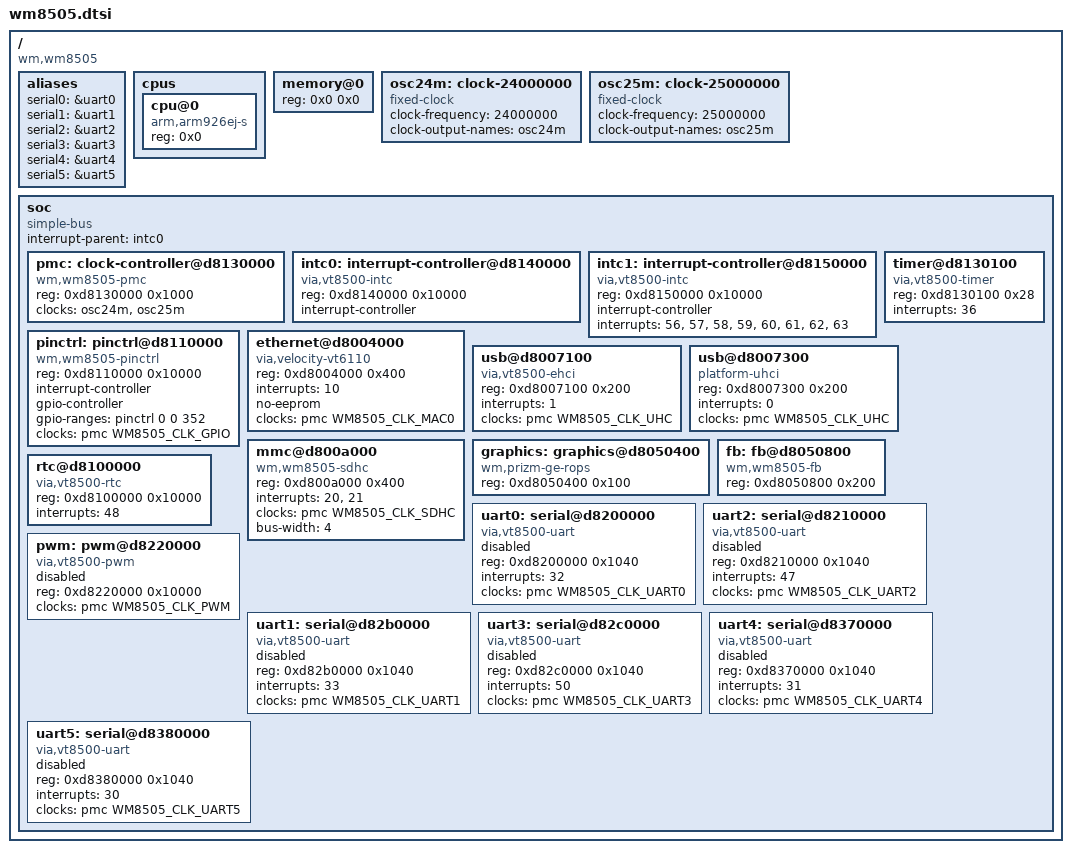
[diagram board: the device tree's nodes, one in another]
// SPDX-License-Identifier: GPL-2.0-or-later
/*
 * wm8505.dtsi - Device tree file for WonderMedia WM8505 SoC
 *
 * Copyright (C) 2012 Tony Prisk <linux@prisktech.co.nz>
 * Copyright (C) 2026 Logan Russell <me@lrussell.net>
 */

#include <dt-bindings/gpio/gpio.h>
#include <dt-bindings/interrupt-controller/irq.h>
#include <dt-bindings/clock/wm8505-clock.h>

/ {
	compatible = "wm,wm8505";
	#address-cells = <1>;
	#size-cells = <1>;

	aliases {
		serial0 = &uart0;
		serial1 = &uart1;
		serial2 = &uart2;
		serial3 = &uart3;
		serial4 = &uart4;
		serial5 = &uart5;
	};

	cpus {
		#address-cells = <1>;
		#size-cells = <0>;

		cpu@0 {
			compatible = "arm,arm926ej-s";
			device_type = "cpu";
			reg = <0x0>;
		};
	};

	memory@0 {
		device_type = "memory";
		reg = <0x0 0x0>;
	};

	osc24m: clock-24000000 {
		compatible = "fixed-clock";
		#clock-cells = <0>;
		clock-frequency = <24000000>;
		clock-output-names = "osc24m";
	};

	osc25m: clock-25000000 {
		compatible = "fixed-clock";
		#clock-cells = <0>;
		clock-frequency = <25000000>;
		clock-output-names = "osc25m";
	};

	soc {
		compatible = "simple-bus";
		#address-cells = <1>;
		#size-cells = <1>;
		ranges;
		interrupt-parent = <&intc0>;

		pmc: clock-controller@d8130000 {
			compatible = "wm,wm8505-pmc";
			reg = <0xd8130000 0x1000>;
			#clock-cells = <1>;
			clocks = <&osc24m>, <&osc25m>;
			clock-names = "osc24m", "osc25m";
		};

		intc0: interrupt-controller@d8140000 {
			compatible = "via,vt8500-intc";
			reg = <0xd8140000 0x10000>;
			interrupt-controller;
			#interrupt-cells = <1>;
		};

		intc1: interrupt-controller@d8150000 {
			compatible = "via,vt8500-intc";
			reg = <0xd8150000 0x10000>;
			interrupt-controller;
			#interrupt-cells = <1>;
			/* Secondary IC cascaded to intc0 */
			interrupts = <56>, <57>, <58>, <59>, <60>, <61>, <62>, <63>;
		};

		pinctrl: pinctrl@d8110000 {
			compatible = "wm,wm8505-pinctrl";
			reg = <0xd8110000 0x10000>;
			interrupt-controller;
			#interrupt-cells = <2>;
			gpio-controller;
			#gpio-cells = <2>;
			gpio-ranges = <&pinctrl 0 0 352>;
			clocks = <&pmc WM8505_CLK_GPIO>;
		};

		timer@d8130100 {
			compatible = "via,vt8500-timer";
			reg = <0xd8130100 0x28>;
			interrupts = <36>;
		};

		ethernet@d8004000 {
			compatible = "via,velocity-vt6110";
			reg = <0xd8004000 0x400>;
			interrupts = <10>;
			no-eeprom;
			clocks = <&pmc WM8505_CLK_MAC0>;
		};

		usb@d8007100 {
			compatible = "via,vt8500-ehci";
			reg = <0xd8007100 0x200>;
			interrupts = <1>;
			clocks = <&pmc WM8505_CLK_UHC>;
		};

		usb@d8007300 {
			compatible = "platform-uhci";
			reg = <0xd8007300 0x200>;
			interrupts = <0>;
			clocks = <&pmc WM8505_CLK_UHC>;
		};

		mmc@d800a000 {
			compatible = "wm,wm8505-sdhc";
			reg = <0xd800a000 0x400>;
			interrupts = <20>, <21>;
			clocks = <&pmc WM8505_CLK_SDHC>;
			bus-width = <4>;
		};

		graphics: graphics@d8050400 {
			compatible = "wm,prizm-ge-rops";
			reg = <0xd8050400 0x100>;
		};

		fb: fb@d8050800 {
			compatible = "wm,wm8505-fb";
			reg = <0xd8050800 0x200>;
		};

		rtc@d8100000 {
			compatible = "via,vt8500-rtc";
			reg = <0xd8100000 0x10000>;
			interrupts = <48>;
		};

		uart0: serial@d8200000 {
			compatible = "via,vt8500-uart";
			reg = <0xd8200000 0x1040>;
			interrupts = <32>;
			clocks = <&pmc WM8505_CLK_UART0>;
			status = "disabled";
		};

		uart2: serial@d8210000 {
			compatible = "via,vt8500-uart";
			reg = <0xd8210000 0x1040>;
			interrupts = <47>;
			clocks = <&pmc WM8505_CLK_UART2>;
			status = "disabled";
		};

		pwm: pwm@d8220000 {
			compatible = "via,vt8500-pwm";
			reg = <0xd8220000 0x10000>;
			#pwm-cells = <2>;
			clocks = <&pmc WM8505_CLK_PWM>;
			status = "disabled";
		};

		uart1: serial@d82b0000 {
			compatible = "via,vt8500-uart";
			reg = <0xd82b0000 0x1040>;
			interrupts = <33>;
			clocks = <&pmc WM8505_CLK_UART1>;
			status = "disabled";
		};

		uart3: serial@d82c0000 {
			compatible = "via,vt8500-uart";
			reg = <0xd82c0000 0x1040>;
			interrupts = <50>;
			clocks = <&pmc WM8505_CLK_UART3>;
			status = "disabled";
		};

		uart4: serial@d8370000 {
			compatible = "via,vt8500-uart";
			reg = <0xd8370000 0x1040>;
			interrupts = <31>;
			clocks = <&pmc WM8505_CLK_UART4>;
			status = "disabled";
		};

		uart5: serial@d8380000 {
			compatible = "via,vt8500-uart";
			reg = <0xd8380000 0x1040>;
			interrupts = <30>;
			clocks = <&pmc WM8505_CLK_UART5>;
			status = "disabled";
		};
	};
};
